# EFM32GG12B810F1024GQ100 register map
File version: 3.0.0
CPU: CM4 r0p1, little endian, MPU, FPU, 3 interrupt priority bits
Registers are 32-bit, read-write, reset 0x0 unless marked. A register's access mark holds for its fields unless they carry their own. Offsets are from the block's base; [hi:lo] are bit positions.

## MSC
Base 0x40000000
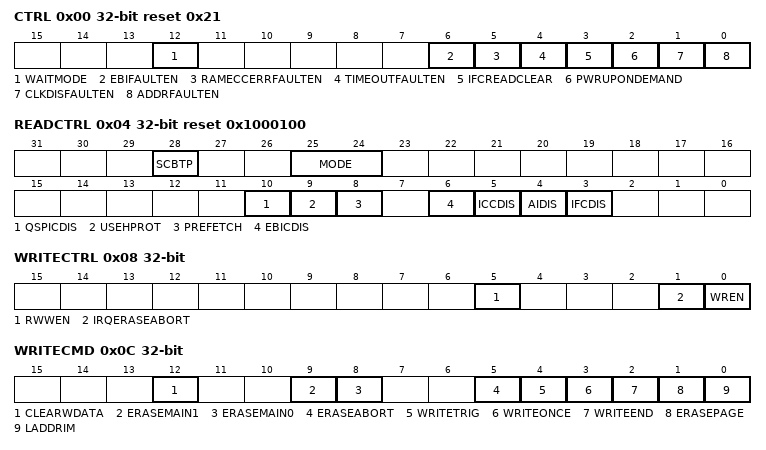
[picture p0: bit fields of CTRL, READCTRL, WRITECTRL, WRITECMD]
0x00 CTRL reset 0x21 — Memory System Control Register
  [12] WAITMODE — Peripheral Access Wait Mode
  [6] EBIFAULTEN — EBI Bus Fault Response Enable
  [5] RAMECCERRFAULTEN — Two Bit ECC Error Bus Fault Response Enable
  [4] TIMEOUTFAULTEN — Timeout Bus Fault Response Enable
  [3] IFCREADCLEAR — IFC Read Clears IF
  [2] PWRUPONDEMAND — Power Up on Demand During Wake Up
  [1] CLKDISFAULTEN — Clock-disabled Bus Fault Response Enable
  [0] ADDRFAULTEN — Invalid Address Bus Fault Response Enable
0x04 READCTRL reset 0x1000100 — Read Control Register
  [28] SCBTP — Suppress Conditional Branch Target Perfetch
  [25:24] MODE — Read Mode
    0=WS0 (Zero wait-states inserted in fetch or read transfers); 1=WS1 (One wait-state inserted for each fetch or read transfer. See Flash Wait-States table for details); 2=WS2 (Two wait-states inserted for eatch fetch or read transfer. See Flash Wait-States table for details); 3=WS3 (Three wait-states inserted for eatch fetch or read transfer. See Flash Wait-States table for details)
  [10] QSPICDIS — QSPI Cache Disable
  [9] USEHPROT — AHB_HPROT Mode
  [8] PREFETCH — Prefetch Mode
  [6] EBICDIS — External Bus Interface Cache Disable
  [5] ICCDIS — Interrupt Context Cache Disable
  [4] AIDIS — Automatic Invalidate Disable
  [3] IFCDIS — Internal Flash Cache Disable
0x08 WRITECTRL — Write Control Register
  [5] RWWEN — Read-While-Write Enable
  [1] IRQERASEABORT — Abort Page Erase on Interrupt
  [0] WREN — Enable Write/Erase Controller
0x0C WRITECMD wo — Write Command Register
  [12] CLEARWDATA — Clear WDATA State
  [9] ERASEMAIN1 — Mass Erase Region 1
  [8] ERASEMAIN0 — Mass Erase Region 0
  [5] ERASEABORT — Abort Erase Sequence
  [4] WRITETRIG — Word Write Sequence Trigger
  [3] WRITEONCE — Word Write-Once Trigger
  [2] WRITEEND — End Write Mode
  [1] ERASEPAGE
  [0] LADDRIM — Load MSC_ADDRB Into ADDR
0x10 ADDRB — Page Erase/Write Address Buffer
  [31:0] ADDRB — Page Erase or Write Address Buffer
0x18 WDATA — Write Data Register
  [31:0] WDATA — Write Data
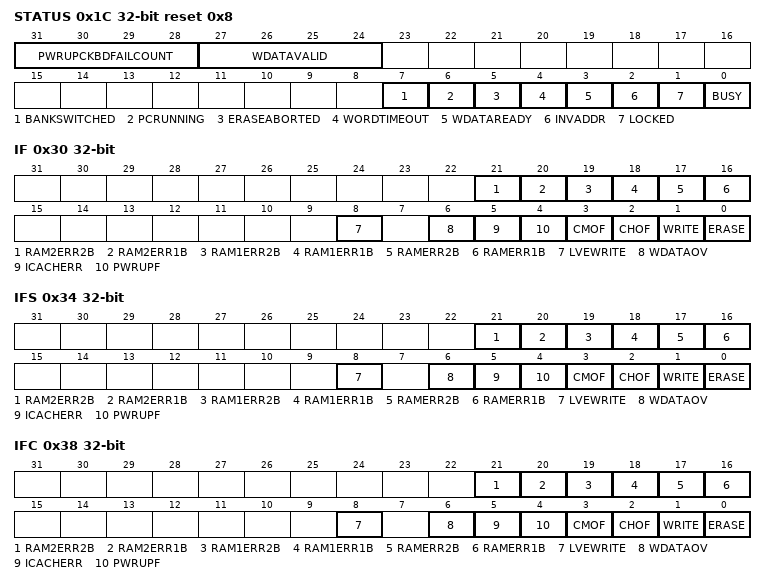
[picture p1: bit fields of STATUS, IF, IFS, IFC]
0x1C STATUS ro reset 0x8
  [31:28] PWRUPCKBDFAILCOUNT — Flash Power Up Checkerboard Pattern Check Fail Count
  [27:24] WDATAVALID — Write Data Buffer Valid Flag
  [7] BANKSWITCHED — BANK SWITCHING STATUS
  [6] PCRUNNING — Performance Counters Running
  [5] ERASEABORTED — The Current Flash Erase Operation Aborted
  [4] WORDTIMEOUT — Flash Write Word Timeout
  [3] WDATAREADY — WDATA Write Ready
  [2] INVADDR — Invalid Write Address or Erase Page
  [1] LOCKED — Access Locked
  [0] BUSY — Erase/Write Busy
0x30 IF ro — Interrupt Flag Register
  [21] RAM2ERR2B — RAM2 2-bit ECC Error Interrupt Flag
  [20] RAM2ERR1B — RAM2 1-bit ECC Error Interrupt Flag
  [19] RAM1ERR2B — RAM1 2-bit ECC Error Interrupt Flag
  [18] RAM1ERR1B — RAM1 1-bit ECC Error Interrupt Flag
  [17] RAMERR2B — RAM 2-bit ECC Error Interrupt Flag
  [16] RAMERR1B — RAM 1-bit ECC Error Interrupt Flag
  [8] LVEWRITE — Flash LVE Write Error Flag
  [6] WDATAOV — Flash Controller Write Buffer Overflow
  [5] ICACHERR — ICache RAM Parity Error Flag
  [4] PWRUPF — Flash Power Up Sequence Complete Flag
  [3] CMOF — Cache Misses Overflow Interrupt Flag
  [2] CHOF — Cache Hits Overflow Interrupt Flag
  [1] WRITE — Write Done Interrupt Read Flag
  [0] ERASE — Erase Done Interrupt Read Flag
0x34 IFS wo — Interrupt Flag Set Register
  [21] RAM2ERR2B — Set RAM2ERR2B Interrupt Flag
  [20] RAM2ERR1B — Set RAM2ERR1B Interrupt Flag
  [19] RAM1ERR2B — Set RAM1ERR2B Interrupt Flag
  [18] RAM1ERR1B — Set RAM1ERR1B Interrupt Flag
  [17] RAMERR2B — Set RAMERR2B Interrupt Flag
  [16] RAMERR1B — Set RAMERR1B Interrupt Flag
  [8] LVEWRITE — Set LVEWRITE Interrupt Flag
  [6] WDATAOV — Set WDATAOV Interrupt Flag
  [5] ICACHERR — Set ICACHERR Interrupt Flag
  [4] PWRUPF — Set PWRUPF Interrupt Flag
  [3] CMOF — Set CMOF Interrupt Flag
  [2] CHOF — Set CHOF Interrupt Flag
  [1] WRITE — Set WRITE Interrupt Flag
  [0] ERASE — Set ERASE Interrupt Flag
0x38 IFC wo — Interrupt Flag Clear Register
  [21] RAM2ERR2B — Clear RAM2ERR2B Interrupt Flag
  [20] RAM2ERR1B — Clear RAM2ERR1B Interrupt Flag
  [19] RAM1ERR2B — Clear RAM1ERR2B Interrupt Flag
  [18] RAM1ERR1B — Clear RAM1ERR1B Interrupt Flag
  [17] RAMERR2B — Clear RAMERR2B Interrupt Flag
  [16] RAMERR1B — Clear RAMERR1B Interrupt Flag
  [8] LVEWRITE — Clear LVEWRITE Interrupt Flag
  [6] WDATAOV — Clear WDATAOV Interrupt Flag
  [5] ICACHERR — Clear ICACHERR Interrupt Flag
  [4] PWRUPF — Clear PWRUPF Interrupt Flag
  [3] CMOF — Clear CMOF Interrupt Flag
  [2] CHOF — Clear CHOF Interrupt Flag
  [1] WRITE — Clear WRITE Interrupt Flag
  [0] ERASE — Clear ERASE Interrupt Flag
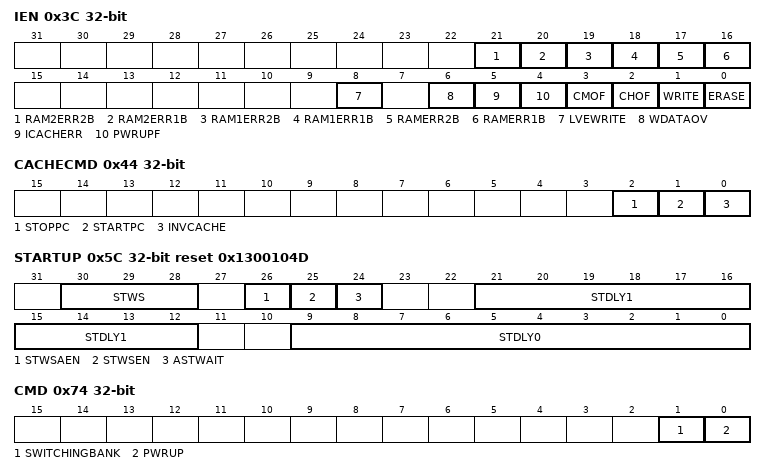
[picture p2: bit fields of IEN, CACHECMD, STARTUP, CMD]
0x3C IEN — Interrupt Enable Register
  [21] RAM2ERR2B — RAM2ERR2B Interrupt Enable
  [20] RAM2ERR1B — RAM2ERR1B Interrupt Enable
  [19] RAM1ERR2B — RAM1ERR2B Interrupt Enable
  [18] RAM1ERR1B — RAM1ERR1B Interrupt Enable
  [17] RAMERR2B — RAMERR2B Interrupt Enable
  [16] RAMERR1B — RAMERR1B Interrupt Enable
  [8] LVEWRITE — LVEWRITE Interrupt Enable
  [6] WDATAOV — WDATAOV Interrupt Enable
  [5] ICACHERR — ICACHERR Interrupt Enable
  [4] PWRUPF — PWRUPF Interrupt Enable
  [3] CMOF — CMOF Interrupt Enable
  [2] CHOF — CHOF Interrupt Enable
  [1] WRITE — WRITE Interrupt Enable
  [0] ERASE — ERASE Interrupt Enable
0x40 LOCK — Configuration Lock Register
  [15:0] LOCKKEY — Configuration Lock
    0=UNLOCKED; 1=LOCKED
0x44 CACHECMD wo — Flash Cache Command Register
  [2] STOPPC — Stop Performance Counters
  [1] STARTPC — Start Performance Counters
  [0] INVCACHE — Invalidate Instruction Cache
0x48 CACHEHITS ro — Cache Hits Performance Counter
  [19:0] CACHEHITS — Cache Hits Since Last Performance Counter Start Command
0x4C CACHEMISSES ro — Cache Misses Performance Counter
  [19:0] CACHEMISSES — Cache Misses Since Last Performance Counter Start Command
0x54 MASSLOCK reset 0x1 — Mass Erase Lock Register
  [15:0] LOCKKEY — Mass Erase Lock
    0=UNLOCKED; 1=LOCKED
0x5C STARTUP reset 0x1300104D — Startup Control
  [30:28] STWS — Startup Waitstates
  [26] STWSAEN — Startup Waitstates Always Enable
  [25] STWSEN — Startup Waitstates Enable
  [24] ASTWAIT — Active Startup Wait
  [21:12] STDLY1 — Startup Delay 0
  [9:0] STDLY0 — Startup Delay 0
0x70 BANKSWITCHLOCK reset 0x1 — Bank Switching Lock Register
  [15:0] BANKSWITCHLOCKKEY — Bank Switching Lock
    0=UNLOCKED; 1=LOCKED
0x74 CMD wo — Command Register
  [1] SWITCHINGBANK — BANK SWITCHING COMMAND
  [0] PWRUP — Flash Power Up Command
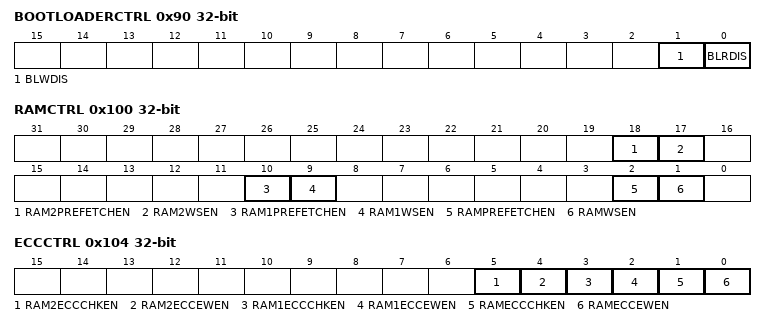
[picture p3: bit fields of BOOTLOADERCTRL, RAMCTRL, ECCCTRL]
0x90 BOOTLOADERCTRL — Bootloader Read and Write Enable, Write Once Register
  [1] BLWDIS — Flash Bootloader Write/Erase Disable
  [0] BLRDIS — Flash Bootloader Read Disable
0x94 AAPUNLOCKCMD wo — Software Unlock AAP Command Register
  [0] UNLOCKAAP — Software Unlock AAP Command
0x98 CACHECONFIG0 reset 0x3 — Cache Configuration Register 0
  [1:0] CACHELPLEVEL — Instruction Cache Low-Power Level
    0=BASE (Base instruction cache functionality.); 1=ADVANCED (Advanced buffering mode, where the cache uses the fetch pattern to predict highly accessed data and store it in low-energy memory.); 3=MINACTIVITY (Minimum activity mode, which allows the cache to minimize activity in logic that it predicts has a low probability being used. This mode can introduce wait-states into the instruction fetch stream when the cache exits one of its low-activity states. The number of wait-states introduced is small, but users running with 0-wait-state memory and wishing to reduce the variability that the cache might introduce with additional wait-states may wish to lower the cache low-power level. Note, this mode includes the advanced buffering mode functionality.)
0x100 RAMCTRL — RAM Control Enable Register
  [18] RAM2PREFETCHEN — RAM2 Prefetch Enable
  [17] RAM2WSEN — RAM2 WAIT STATE Enable
  [10] RAM1PREFETCHEN — RAM1 Prefetch Enable
  [9] RAM1WSEN — RAM1 WAIT STATE Enable
  [2] RAMPREFETCHEN — RAM Prefetch Enable
  [1] RAMWSEN — RAM WAIT STATE Enable
0x104 ECCCTRL — RAM ECC Control Register
  [5] RAM2ECCCHKEN — RAM2 ECC Check Enable
  [4] RAM2ECCEWEN — RAM2 ECC Write Enable
  [3] RAM1ECCCHKEN — RAM1 ECC Check Enable
  [2] RAM1ECCEWEN — RAM1 ECC Write Enable
  [1] RAMECCCHKEN — RAM ECC Check Enable
  [0] RAMECCEWEN — RAM ECC Write Enable
0x108 RAMECCADDR ro — RAM ECC Error Address Register
  [31:0] RAMECCADDR — RAM ECC Error Address
0x10C RAM1ECCADDR ro — RAM1 ECC Error Address Register
  [31:0] RAM1ECCADDR — RAM1 ECC Error Address
0x110 RAM2ECCADDR ro — RAM2 ECC Error Address Register
  [31:0] RAM2ECCADDR — RAM2 ECC Error Address

## Notices in the file
# License
Copyright 2020 Silicon Laboratories Inc. www.silabs.com
SPDX-License-Identifier: Zlib
The licensor of this software is Silicon Laboratories Inc.
This software is provided 'as-is', without any express or implied
warranty. In no event will the authors be held liable for any damages
arising from the use of this software.
Permission is granted to anyone to use this software for any purpose,
including commercial applications, and to alter it and redistribute it
freely, subject to the following restrictions:
1. The origin of this software must not be misrepresented; you must not
claim that you wrote the original software. If you use this software
in a product, an acknowledgment in the product documentation would be
appreciated but is not required.
2. Altered source versions must be plainly marked as such, and must not be
misrepresented as being the original software.
3. This notice may not be removed or altered from any source distribution.
